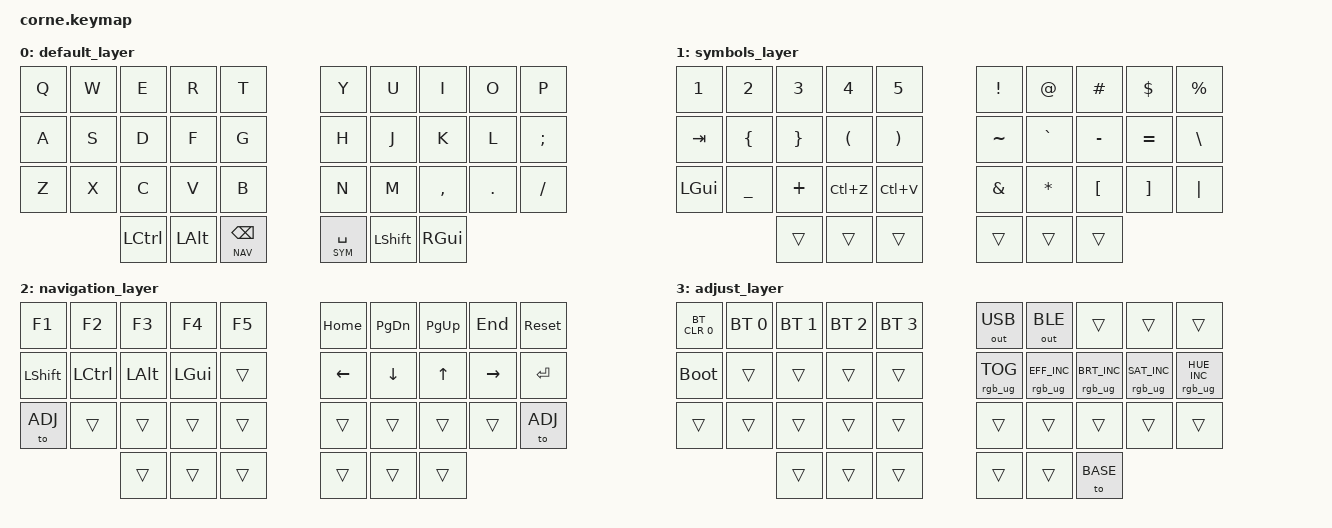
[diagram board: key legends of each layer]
/*
 * corne.keymap
 * Versie 3.0 - Definitieve, stabiele versie.
 */

#include <behaviors.dtsi>
#include <dt-bindings/zmk/keys.h>
#include <dt-bindings/zmk/rgb.h>
#include <dt-bindings/zmk/bt.h>
#include <dt-bindings/zmk/outputs.h>

// Definieer aliassen voor de lagen voor betere leesbaarheid.
#define BASE 0
#define SYM  1
#define NAV  2
#define ADJ  3

/ {
    keymap {
        compatible = "zmk,keymap";

        // -----------------------------------------------------------------------------
        // Laag 0: BASE (QWERTY)
        // De duimtoetsen gebruiken de ingebouwde '&lt' (layer-tap) behavior.
        // Syntax: &lt LAAG_NUMMER TOETS_BIJ_TIKKEN
        // -----------------------------------------------------------------------------
        default_layer {
            bindings = <
            // Linkerhelft                                                       // Rechterhelft
            &kp Q      &kp W      &kp E      &kp R      &kp T                       &kp Y      &kp U      &kp I      &kp O      &kp P
            &kp A      &kp S      &kp D      &kp F      &kp G                       &kp H      &kp J      &kp K      &kp L      &kp SEMI
            &kp Z      &kp X      &kp C      &kp V      &kp B                       &kp N      &kp M      &kp COMMA  &kp DOT    &kp FSLH
                                  &kp LCTRL  &kp LALT   &lt NAV BSPC                  &lt SYM SPACE &kp LSHFT  &kp RGUI
            >;
        };

        // -----------------------------------------------------------------------------
        // Laag 1: SYMBOLS (Cijfers & Symbolen)
        // -----------------------------------------------------------------------------
        symbols_layer {
            bindings = <
            // Linkerhelft                                                       // Rechterhelft
            &kp N1     &kp N2     &kp N3     &kp N4     &kp N5                      &kp EXCL   &kp AT     &kp HASH   &kp DLLR   &kp PRCNT
            &kp TAB    &kp LBRC   &kp RBRC   &kp LPAR   &kp RPAR                    &kp TILDE  &kp GRAVE  &kp MINUS  &kp EQUAL  &kp BSLH
            &kp LGUI   &kp UNDER  &kp PLUS   &kp LC(Z)  &kp LC(V)                   &kp AMPS   &kp STAR   &kp LBKT   &kp RBKT   &kp PIPE
                                  &trans     &trans     &trans                      &trans     &trans     &trans
            >;
        };

        // -----------------------------------------------------------------------------
        // Laag 2: NAVIGATION (Pijltjes & Functietoetsen)
        // -----------------------------------------------------------------------------
        navigation_layer {
            bindings = <
            // Linkerhelft                                                       // Rechterhelft
            &kp F1     &kp F2     &kp F3     &kp F4     &kp F5                      &kp HOME   &kp PG_DN  &kp PG_UP  &kp END    &sys_reset
            &kp LSHFT  &kp LCTRL  &kp LALT   &kp LGUI   &trans                      &kp LEFT   &kp DOWN   &kp UP     &kp RIGHT  &kp ENTER
            &to ADJ    &trans     &trans     &trans     &trans                      &trans     &trans     &trans     &trans     &to ADJ
                                  &trans     &trans     &trans                      &trans     &trans     &trans
            >;
        };

        // -----------------------------------------------------------------------------
        // Laag 3: ADJUST (Systeem & RGB/BT Controle)
        // -----------------------------------------------------------------------------
        adjust_layer {
            bindings = <
            // Linkerhelft                                                       // Rechterhelft
            &bt BT_CLR 0 &bt BT_SEL 0 &bt BT_SEL 1 &bt BT_SEL 2 &bt BT_SEL 3      &out OUT_USB &out OUT_BLE &trans          &trans          &trans
            &bootloader  &trans     &trans     &trans     &trans                      &rgb_ug RGB_TOG &rgb_ug RGB_EFF_INC &rgb_ug RGB_BRT_INC &rgb_ug RGB_SAT_INC &rgb_ug RGB_HUE_INC
            &trans     &trans     &trans     &trans     &trans                      &trans          &trans          &trans          &trans          &trans
                                  &trans     &trans     &trans                      &trans          &trans          &to BASE
            >;
        };
    };
};
